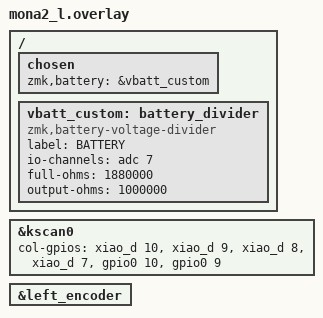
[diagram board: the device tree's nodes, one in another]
#include "mona2.dtsi"

/ {
    /* 1. chosen で自作ノードを指定 */
    chosen {
        zmk,battery = &vbatt_custom;
    };

    /* 2. ノードの本体を定義 */
    vbatt_custom: battery_divider {
        compatible = "zmk,battery-voltage-divider";
        label = "BATTERY";
        io-channels = <&adc 7>; 
        full-ohms = <1880000>;
        output-ohms = <1000000>;
    };
};

&kscan0 {
        col-gpios
            = <&xiao_d 10 GPIO_ACTIVE_HIGH>
            , <&xiao_d 9 GPIO_ACTIVE_HIGH> 
            , <&xiao_d 8 GPIO_ACTIVE_HIGH> 
            , <&xiao_d 7 GPIO_ACTIVE_HIGH> 
            , <&gpio0 10 GPIO_ACTIVE_HIGH>
            , <&gpio0 9 GPIO_ACTIVE_HIGH>
            ;
};

&left_encoder {
    status = "okay";
};
